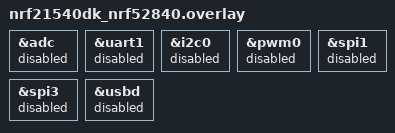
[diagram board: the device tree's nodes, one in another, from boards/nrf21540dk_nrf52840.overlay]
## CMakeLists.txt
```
#
# Copyright (c) 2021 Nordic Semiconductor ASA
#
# SPDX-License-Identifier: LicenseRef-Nordic-5-Clause
#

cmake_minimum_required(VERSION 3.20.0)

find_package(Zephyr HINTS $ENV{ZEPHYR_BASE})

project(matter-light-switch)

# Enable GNU STD support.
include(${ZEPHYR_CONNECTEDHOMEIP_MODULE_DIR}/config/nrfconnect/app/enable-gnu-std.cmake)

# NORDIC SDK APP START

# Include all source files that are located in the Matter common directory.
include(${ZEPHYR_NRF_MODULE_DIR}/samples/matter/common/cmake/source_common.cmake)

# Include Data Model utils
include(${ZEPHYR_NRF_MODULE_DIR}/samples/matter/common/cmake/data_model.cmake)

include(${ZEPHYR_NRF_MODULE_DIR}/samples/matter/common/cmake/zap_helpers.cmake)
ncs_get_zap_parent_dir(ZAP_PARENT_DIR)

target_include_directories(app PRIVATE
  src
  ${ZAP_PARENT_DIR}
)

target_compile_options(app PRIVATE -Wno-deprecated-declarations)

target_sources(app PRIVATE
  src/app_task.cpp
  src/main.cpp
  src/shell_commands.cpp
  ${ZEPHYR_NRF_MODULE_DIR}/samples/matter/common/src/binding/binding_handler.cpp
)

target_sources_ifdef(CONFIG_GENERIC_SWITCH app PRIVATE src/generic_switch.cpp)
target_sources_ifdef(CONFIG_LIGHT_SWITCH app PRIVATE src/light_switch.cpp)

ncs_configure_data_model()
# NORDIC SDK APP END
```

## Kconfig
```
#
# Copyright (c) 2022 Nordic Semiconductor
#
# SPDX-License-Identifier: LicenseRef-Nordic-5-Clause
#
mainmenu "Matter nRF Connect Light Switch Example Application"

config STATE_LEDS
	bool "Use LEDs to indicate the device state"
	default y
	help
	  Use LEDs to render the current state of the device such as the progress of commissioning of
	  the device into a network or the factory reset initiation. Note that setting this option to
	  'n' does not disable the LED indicating the state of the simulated bolt.

choice SWITCH_TYPE
	prompt "Matter Switch Type"
	default LIGHT_SWITCH
	help
	  Choose the type of switch to act as.

config LIGHT_SWITCH
	bool "Act as a Light Switch"
	help
	  Act as a Light Switch, which uses client application clusters (for example, Level Control) and bindings to send commands to the server clusters.

config GENERIC_SWITCH
	bool "Act as a Generic Switch"
	help
	  Act as a Generic Switch, which implements the Momentary Switch (`MS`) and Momentary Switch Release (`MSR`) features.

endchoice

# Sample configuration used for Thread networking
if OPENTHREAD

choice OPENTHREAD_NORDIC_LIBRARY_CONFIGURATION
	default OPENTHREAD_NORDIC_LIBRARY_MTD
endchoice

choice OPENTHREAD_DEVICE_TYPE
	default OPENTHREAD_MTD
endchoice

config CHIP_ENABLE_ICD_SUPPORT
	default y

# Reduce Thread TX output power to 0 dBm for SED device
config OPENTHREAD_DEFAULT_TX_POWER
	default 0

endif # OPENTHREAD

if BOARD_NRF7002DK_NRF5340_CPUAPP || SHIELD_NRF7002EB2

config CHIP_WIFI
	default y
	select DEPRECATED if SOC_SERIES_NRF53X

config NRF_WIFI_LOW_POWER
	default y

endif # BOARD_NRF7002DK_NRF5340_CPUAPP || SHIELD_NRF7002EB2

# Enable Read Client functionality for all build configurations.
config CHIP_ENABLE_READ_CLIENT
	default y

source "$(ZEPHYR_CONNECTEDHOMEIP_MODULE_DIR)/config/nrfconnect/chip-module/Kconfig.features"
source "$(ZEPHYR_CONNECTEDHOMEIP_MODULE_DIR)/config/nrfconnect/chip-module/Kconfig.defaults"
source "$(ZEPHYR_NRF_MODULE_DIR)/samples/matter/common/src/Kconfig"
source "Kconfig.zephyr"
```

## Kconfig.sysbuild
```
#
# Copyright (c) 2023 Nordic Semiconductor ASA
#
# SPDX-License-Identifier: LicenseRef-Nordic-5-Clause
#

config PARTITION_MANAGER
	default n if SOC_SERIES_NRF52X || SOC_NRF54L15 || SOC_NRF54LM20A

# This config has to be enabled manually for variants with shields, because sysbuild does not support it.
config WIFI_NRF70
	default y if BOARD_NRF7002DK

#### Radio core selection
config NRF_DEFAULT_IPC_RADIO
	default y

# Enable IEEE802.15.4 serialization to network core
# This config automatically pulls in the `overlay-802154.conf` in the ipc_radio image
config NETCORE_IPC_RADIO_IEEE802154
	default y if SOC_SERIES_NRF53X && !WIFI_NRF70

# Enable Bluetooth serialization to network core
# This config automatically pulls in the `overlay-bt_hci_ipc.conf` in the ipc_radio image
config NETCORE_IPC_RADIO_BT_HCI_IPC
	default y if SOC_SERIES_NRF53X

#### Bootloader
choice BOOTLOADER
	default BOOTLOADER_MCUBOOT if !BOARD_NRF21540DK
endchoice

if BOOTLOADER_MCUBOOT

#### DFU multi-image support
config DFU_MULTI_IMAGE_PACKAGE_BUILD
	default y

config DFU_MULTI_IMAGE_PACKAGE_APP
	default y

config PM_EXTERNAL_FLASH_MCUBOOT_SECONDARY
	default y

#### DFU network core configuration
if SOC_SERIES_NRF53X

choice MCUBOOT_MODE
	default MCUBOOT_MODE_OVERWRITE_ONLY
endchoice

choice BOOT_SIGNATURE_TYPE
	default BOOT_SIGNATURE_TYPE_RSA
endchoice

config SECURE_BOOT_NETCORE
	default y

config NETCORE_APP_UPDATE
	default y

config DFU_MULTI_IMAGE_PACKAGE_NET
	default y

endif # SOC_SERIES_NRF53X

if BOARD_NRF54L15DK || BOARD_NRF54LM20DK

# Disable checking the external drivers for nRF54L15 and nRF54LM20 DKs.
config PM_OVERRIDE_EXTERNAL_DRIVER_CHECK
	default y

endif # BOARD_NRF54L15DK || BOARD_NRF54LM20DK

endif # BOOTLOADER_MCUBOOT

# Store the Wi-Fi firmware patch on external flash by default for nRF5340 with nRF7002
if WIFI_NRF70 && SOC_NRF5340_CPUAPP

choice WIFI_PATCHES_EXT_FLASH_SUPPORT
	default WIFI_PATCHES_EXT_FLASH_STORE

endchoice

config DFU_MULTI_IMAGE_PACKAGE_WIFI_FW_PATCH
	default y

endif # WIFI_NRF70

#### Enable generating factory data
config MATTER_FACTORY_DATA_GENERATE
	default y if !BOARD_NRF21540DK

source "share/sysbuild/Kconfig"
```

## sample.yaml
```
sample:
  description: Matter Light Switch example
  name: Matter Light Switch
common:
  tags:
    - sysbuild
    - ci_samples_matter
tests:
  sample.matter.light_switch.debug:
    sysbuild: true
    build_only: true
    integration_platforms:
      - nrf52840dk/nrf52840
      - nrf5340dk/nrf5340/cpuapp
      - nrf7002dk/nrf5340/cpuapp
      - nrf54l15dk/nrf54l15/cpuapp
      - nrf54l15dk/nrf54l15/cpuapp/ns
      - nrf54lm20dk/nrf54lm20a/cpuapp
    platform_allow:
      - nrf52840dk/nrf52840
      - nrf5340dk/nrf5340/cpuapp
      - nrf7002dk/nrf5340/cpuapp
      - nrf54l15dk/nrf54l15/cpuapp
      - nrf54l15dk/nrf54l15/cpuapp/ns
      - nrf54lm20dk/nrf54lm20a/cpuapp
  sample.matter.light_switch.nrf7002eb2.debug:
    sysbuild: true
    build_only: true
    extra_args:
      - light_switch_SHIELD=nrf7002eb2
      - SB_CONFIG_WIFI_NRF70=y
    integration_platforms:
      - nrf54lm20dk/nrf54lm20a/cpuapp
    platform_allow:
      - nrf54lm20dk/nrf54lm20a/cpuapp
  sample.matter.light_switch.release:
    sysbuild: true
    build_only: true
    extra_args:
      - FILE_SUFFIX=release
      - SB_CONFIG_BOOTLOADER_MCUBOOT=y
      - SB_CONFIG_PARTITION_MANAGER=y
    integration_platforms:
      - nrf52840dk/nrf52840
      - nrf5340dk/nrf5340/cpuapp
      - nrf7002dk/nrf5340/cpuapp
      - nrf54l15dk/nrf54l15/cpuapp
      - nrf54lm20dk/nrf54lm20a/cpuapp
    platform_allow:
      - nrf52840dk/nrf52840
      - nrf5340dk/nrf5340/cpuapp
      - nrf7002dk/nrf5340/cpuapp
      - nrf54l15dk/nrf54l15/cpuapp
      - nrf54lm20dk/nrf54lm20a/cpuapp
  sample.matter.light_switch.nrf7002eb2.release:
    sysbuild: true
    build_only: true
    extra_args:
      - FILE_SUFFIX=release
      - SB_CONFIG_BOOTLOADER_MCUBOOT=y
      - SB_CONFIG_PARTITION_MANAGER=y
      - light_switch_SHIELD=nrf7002eb2
      - SB_CONFIG_WIFI_NRF70=y
    integration_platforms:
      - nrf54lm20dk/nrf54lm20a/cpuapp
    platform_allow:
      - nrf54lm20dk/nrf54lm20a/cpuapp
  sample.matter.light_switch.lit_icd:
    sysbuild: true
    build_only: true
    extra_args:
      - light_switch_SNIPPET=lit_icd
    integration_platforms:
      - nrf52840dk/nrf52840
      - nrf5340dk/nrf5340/cpuapp
      - nrf54l15dk/nrf54l15/cpuapp
    platform_allow:
      - nrf52840dk/nrf52840
      - nrf5340dk/nrf5340/cpuapp
      - nrf54l15dk/nrf54l15/cpuapp
  sample.matter.light_switch.low_power:
    sysbuild: true
    build_only: true
    extra_args:
      - FILE_SUFFIX=release
      - CONFIG_CHIP_ICD_SLOW_POLL_INTERVAL=7500
      - CONFIG_CHIP_ICD_ACTIVE_MODE_DURATION=800
      - CONFIG_CHIP_ICD_FAST_POLLING_INTERVAL=100
      - CONFIG_CHIP_ICD_ACTIVE_MODE_THRESHOLD=5000
      - CONFIG_OPENTHREAD_DEFAULT_TX_POWER=0
      - CONFIG_NCS_SAMPLE_MATTER_LEDS=n
      - CONFIG_NCS_SAMPLE_MATTER_WATCHDOG=n
      - CONFIG_CHIP_ENABLE_PAIRING_AUTOSTART=y
      - OVERLAY_CONFIG=overlay-generic_switch.conf
    integration_platforms:
      - nrf54lm20dk/nrf54lm20a/cpuapp
    platform_allow:
      - nrf54lm20dk/nrf54lm20a/cpuapp
  sample.matter.light_switch.low_power_dut:
    sysbuild: true
    build_only: true
    extra_args:
      - FILE_SUFFIX=release
      - CONFIG_CHIP_ICD_SLOW_POLL_INTERVAL=7500
      - CONFIG_CHIP_ICD_ACTIVE_MODE_DURATION=800
      - CONFIG_CHIP_ICD_FAST_POLLING_INTERVAL=100
      - CONFIG_CHIP_ICD_ACTIVE_MODE_THRESHOLD=5000
      - CONFIG_OPENTHREAD_DEFAULT_TX_POWER=5
      - CONFIG_NCS_SAMPLE_MATTER_LEDS=n
      - CONFIG_NCS_SAMPLE_MATTER_WATCHDOG=n
      - CONFIG_CHIP_ENABLE_PAIRING_AUTOSTART=y
      - OVERLAY_CONFIG=overlay-generic_switch.conf
    integration_platforms:
      - nrf54lm20dk/nrf54lm20a/cpuapp
    platform_allow:
      - nrf54lm20dk/nrf54lm20a/cpuapp
  sample.matter.light_switch.low_power_max:
    sysbuild: true
    build_only: true
    extra_args:
      - FILE_SUFFIX=release
      - CONFIG_CHIP_ICD_SLOW_POLL_INTERVAL=7500
      - CONFIG_CHIP_ICD_ACTIVE_MODE_DURATION=800
      - CONFIG_CHIP_ICD_FAST_POLLING_INTERVAL=100
      - CONFIG_CHIP_ICD_ACTIVE_MODE_THRESHOLD=5000
      - CONFIG_OPENTHREAD_DEFAULT_TX_POWER=8
      - CONFIG_NCS_SAMPLE_MATTER_LEDS=n
      - CONFIG_NCS_SAMPLE_MATTER_WATCHDOG=n
      - CONFIG_CHIP_ENABLE_PAIRING_AUTOSTART=y
      - OVERLAY_CONFIG=overlay-generic_switch.conf
    integration_platforms:
      - nrf54lm20dk/nrf54lm20a/cpuapp
    platform_allow:
      - nrf54lm20dk/nrf54lm20a/cpuapp
```

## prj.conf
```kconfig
#
# Copyright (c) 2021 Nordic Semiconductor ASA
#
# SPDX-License-Identifier: LicenseRef-Nordic-5-Clause
#

# Enable CHIP
CONFIG_CHIP=y
CONFIG_CHIP_PROJECT_CONFIG="src/chip_project_config.h"
CONFIG_CHIP_DEVICE_PRODUCT_NAME="Matter Light Switch"

# Configure ZAP file name
CONFIG_NCS_SAMPLE_MATTER_ZAP_FILE_PATH="${APPLICATION_CONFIG_DIR}/src/default_zap/light_switch.zap"

# 32772 == 0x8004 (example light-switch-app)
CONFIG_CHIP_DEVICE_PRODUCT_ID=32772
CONFIG_STD_CPP17=y

# Enable Matter pairing automatically on application start.
CONFIG_CHIP_ENABLE_PAIRING_AUTOSTART=y

# Enable Matter extended announcement and increase duration to 1 hour.
CONFIG_CHIP_BLE_EXT_ADVERTISING=y
CONFIG_CHIP_BLE_ADVERTISING_DURATION=60

# Add support for LEDs and buttons on Nordic development kits
CONFIG_DK_LIBRARY=y

# Bluetooth Low Energy configuration
CONFIG_BT_DEVICE_NAME="MatterSwitch"

# Suspend devices when the CPU goes into sleep
CONFIG_PM_DEVICE=y

# Other settings
CONFIG_THREAD_NAME=y
CONFIG_MPU_STACK_GUARD=y
CONFIG_RESET_ON_FATAL_ERROR=n
CONFIG_CHIP_LIB_SHELL=y
CONFIG_NCS_SAMPLE_MATTER_TEST_SHELL=y

# Reduce application size
CONFIG_USE_SEGGER_RTT=n

# Enable Factory Data feature
CONFIG_CHIP_FACTORY_DATA=y
CONFIG_CHIP_FACTORY_DATA_BUILD=y

# Enable LIT ICD configuration
CONFIG_CHIP_ICD_LIT_SUPPORT=y
CONFIG_CHIP_ICD_SIT_SLOW_POLL_LIMIT=5000
CONFIG_CHIP_ICD_REPORT_ON_ACTIVE_MODE=y
```

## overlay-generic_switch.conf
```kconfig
#
# Copyright (c) 2026 Nordic Semiconductor ASA
#
# SPDX-License-Identifier: LicenseRef-Nordic-5-Clause
#

CONFIG_GENERIC_SWITCH=y
CONFIG_NCS_SAMPLE_MATTER_ZAP_FILE_PATH="${APPLICATION_CONFIG_DIR}/src/generic_switch_zap/generic_switch.zap"
```

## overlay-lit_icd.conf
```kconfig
#
# Copyright (c) 2026 Nordic Semiconductor ASA
#
# SPDX-License-Identifier: LicenseRef-Nordic-5-Clause
#
```

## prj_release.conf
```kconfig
#
# Copyright (c) 2021 Nordic Semiconductor ASA
#
# SPDX-License-Identifier: LicenseRef-Nordic-5-Clause
#

# Enable CHIP
CONFIG_CHIP=y
CONFIG_CHIP_PROJECT_CONFIG="src/chip_project_config.h"
CONFIG_CHIP_DEVICE_PRODUCT_NAME="Matter Light Switch"

# Configure ZAP file name
CONFIG_NCS_SAMPLE_MATTER_ZAP_FILE_PATH="${APPLICATION_CONFIG_DIR}/src/default_zap/light_switch.zap"

# 32772 == 0x8004 (example light-switch-app)
CONFIG_CHIP_DEVICE_PRODUCT_ID=32772
CONFIG_STD_CPP17=y

# Enable Matter pairing automatically on application start.
CONFIG_CHIP_ENABLE_PAIRING_AUTOSTART=y

# Enable Matter extended announcement and increase duration to 1 hour.
CONFIG_CHIP_BLE_EXT_ADVERTISING=y
CONFIG_CHIP_BLE_ADVERTISING_DURATION=60

# Add support for LEDs and buttons on Nordic development kits
CONFIG_DK_LIBRARY=y

# Try to disable unused RAM blocks to reduce power consumption
CONFIG_RAM_POWER_DOWN_LIBRARY=y

# Bluetooth Low Energy configuration
CONFIG_BT_DEVICE_NAME="MatterSwitch"

# Suspend devices when the CPU goes into sleep
CONFIG_PM_DEVICE=y

# Enable system reset on fatal error
CONFIG_RESET_ON_FATAL_ERROR=y

# Disable all debug features
CONFIG_USE_SEGGER_RTT=n
CONFIG_SHELL=n
CONFIG_OPENTHREAD_SHELL=n
CONFIG_CONSOLE=n
CONFIG_UART_CONSOLE=n
CONFIG_SERIAL=n
CONFIG_LOG=n
CONFIG_LOG_MODE_MINIMAL=n
CONFIG_ASSERT_VERBOSE=n
CONFIG_ASSERT_NO_FILE_INFO=y
CONFIG_PRINTK=n
CONFIG_PRINTK_SYNC=n
CONFIG_THREAD_NAME=n
CONFIG_BOOT_BANNER=n

# Enable Factory Data feature
CONFIG_CHIP_FACTORY_DATA=y
CONFIG_CHIP_FACTORY_DATA_BUILD=y

# Enable Watchdog
CONFIG_NCS_SAMPLE_MATTER_WATCHDOG=y

# Enable LTO to decrease the flash usage.
CONFIG_LTO=y
CONFIG_ISR_TABLES_LOCAL_DECLARATION=y

# Enable LIT ICD configuration
CONFIG_CHIP_ICD_LIT_SUPPORT=y
CONFIG_CHIP_ICD_SIT_SLOW_POLL_LIMIT=5000
CONFIG_CHIP_ICD_REPORT_ON_ACTIVE_MODE=y
```

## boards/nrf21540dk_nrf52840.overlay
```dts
/* Copyright (c) 2021 Nordic Semiconductor ASA
 *
 * SPDX-License-Identifier: LicenseRef-Nordic-5-Clause
 */

#include <samples/matter/nrf52840_partitions.dtsi>

/* Disable unused peripherals to reduce power consumption */
&adc {
	status = "disabled";
};

&uart1 {
	status = "disabled";
};

&i2c0 {
	status = "disabled";
};

&pwm0 {
	status = "disabled";
};

&spi1 {
	status = "disabled";
};

&spi3 {
	status = "disabled";
};

&usbd {
	status = "disabled";
};
```

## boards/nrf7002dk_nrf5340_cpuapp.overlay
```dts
/*
 * Copyright (c) 2021 Nordic Semiconductor ASA
 *
 * SPDX-License-Identifier: LicenseRef-Nordic-5-Clause
 */

#include <samples/matter/nrf7002_partitions.dtsi>
#include <zephyr/dt-bindings/ipc_service/static_vrings.h>

/ {
	aliases {
		watchdog0 = &wdt0;
	};
};

/* Set IPC thread priority to the highest value to not collide with other threads. */
&ipc0 {
	zephyr,priority = <0 PRIO_COOP>;
};
```

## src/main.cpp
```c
/*
 * Copyright (c) 2022 Nordic Semiconductor ASA
 *
 * SPDX-License-Identifier: LicenseRef-Nordic-5-Clause
 */

#include "app_task.h"

#include <cstdlib>
#include <logging/log.h>

LOG_MODULE_REGISTER(app);

int main()
{
	return GetAppTask().StartApp() == CHIP_NO_ERROR ? EXIT_SUCCESS : EXIT_FAILURE;
}
```

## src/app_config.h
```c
/*
 * Copyright (c) 2022 Nordic Semiconductor ASA
 *
 * SPDX-License-Identifier: LicenseRef-Nordic-5-Clause
 */

#pragma once

// ---- Lighting Example App Config ----

#define FUNCTION_BUTTON DK_BTN1
#define FUNCTION_BUTTON_MASK DK_BTN1_MSK
#define SWITCH_BUTTON DK_BTN2
#define SWITCH_BUTTON_MASK DK_BTN2_MSK
#define BLE_ADVERTISEMENT_START_BUTTON DK_BTN4
#define BLE_ADVERTISEMENT_START_BUTTON_MASK DK_BTN4_MSK

#define SYSTEM_STATE_LED DK_LED1
#define DFU_BLE_LED DK_LED2
#define IDENTIFY_LED DK_LED3
```

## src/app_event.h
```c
/*
 * Copyright (c) 2021 Nordic Semiconductor ASA
 *
 * SPDX-License-Identifier: LicenseRef-Nordic-5-Clause
 */

#pragma once

#include <inet/IPAddress.h>

#include <cstdint>

#include "led_widget.h"

struct AppEvent;
typedef void (*EventHandler)(AppEvent *);

struct AppEvent {
	constexpr static uint8_t kButtonPushEvent = 1;
	constexpr static uint8_t kButtonReleaseEvent = 0;

	enum AppEventTypes : uint8_t {
		kEventType_StartBLEAdvertising,
		kEventType_Button,
		kEventType_Timer,
		kEventType_UpdateLedState,
		kEventType_IdentifyStart,
		kEventType_IdentifyStop,
#ifdef CONFIG_MCUMGR_SMP_BT
		kEventType_StartSMPAdvertising,
#endif
	};

	uint8_t Type;

	union {
		struct {
			uint8_t PinNo;
			uint8_t Action;
		} ButtonEvent;
		struct {
			uint8_t TimerType;
			void *Context;
		} TimerEvent;
		struct {
			LEDWidget *LedWidget;
		} UpdateLedStateEvent;
	};

	EventHandler Handler;
};
```

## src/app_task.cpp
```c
/*
 * Copyright (c) 2022 Nordic Semiconductor ASA
 *
 * SPDX-License-Identifier: LicenseRef-Nordic-5-Clause
 */

#include "app_task.h"

#if defined(CONFIG_LIGHT_SWITCH)
#include "light_switch.h"
#elif defined(CONFIG_GENERIC_SWITCH)
#include "generic_switch.h"
#endif

#include "app/matter_init.h"
#include "app/task_executor.h"
#include "board/board.h"
#include "clusters/identify.h"

#include <setup_payload/OnboardingCodesUtil.h>

#include <zephyr/logging/log.h>

LOG_MODULE_DECLARE(app, CONFIG_CHIP_APP_LOG_LEVEL);

using namespace ::chip;
using namespace ::chip::app;
using namespace ::chip::DeviceLayer;

namespace
{
constexpr uint32_t kDimmerTriggeredTimeout = 500;
constexpr uint32_t kDimmerInterval = 300;
constexpr EndpointId kLightSwitchEndpointId = 1;
constexpr EndpointId kLightEndpointId = 1;

k_timer sDimmerPressKeyTimer;
k_timer sDimmerTimer;

Nrf::Matter::IdentifyCluster sIdentifyCluster(kLightEndpointId);

bool sWasDimmerTriggered = false;

#define APPLICATION_BUTTON_MASK DK_BTN2_MSK

#ifdef CONFIG_CHIP_ICD_UAT_SUPPORT
#define UAT_BUTTON_MASK DK_BTN3_MSK
#endif

#if defined(CONFIG_LIGHT_SWITCH)
	LightSwitch sSwitchInstance(kLightSwitchEndpointId);
#elif defined(CONFIG_GENERIC_SWITCH)
	GenericSwitch sSwitchInstance(kLightSwitchEndpointId);
#endif
} /* namespace */

void AppTask::DimmerTriggerEventHandler()
{
	if (!sWasDimmerTriggered) {
		sSwitchInstance.InitiateActionSwitch(LightSwitch::Action::Toggle);
	}

	Instance().CancelTimer(Timer::Dimmer);
	Instance().CancelTimer(Timer::DimmerTrigger);
	sWasDimmerTriggered = false;
}

void AppTask::TimerEventHandler(const Timer &timerType)
{
	switch (timerType) {
	case Timer::DimmerTrigger:
		LOG_INF("Dimming started...");
		sWasDimmerTriggered = true;
		sSwitchInstance.InitiateActionSwitch(LightSwitch::Action::On);
		Instance().StartTimer(Timer::Dimmer, kDimmerInterval);
		Instance().CancelTimer(Timer::DimmerTrigger);
		break;
	case Timer::Dimmer:
		sSwitchInstance.DimmerChangeBrightness();
		break;
	default:
		break;
	}
}

void AppTask::ButtonEventHandler(Nrf::ButtonState state, Nrf::ButtonMask hasChanged)
{
	if ((APPLICATION_BUTTON_MASK & state & hasChanged)) {
		LOG_INF("Button has been pressed, keep in this state for at least 500 ms to change light sensitivity of bound lighting devices.");
		Instance().StartTimer(Timer::DimmerTrigger, kDimmerTriggeredTimeout);
	} else if ((APPLICATION_BUTTON_MASK & hasChanged)) {
		Nrf::PostTask([] { DimmerTriggerEventHandler(); });
#ifdef CONFIG_CHIP_ICD_UAT_SUPPORT
	} else if ((UAT_BUTTON_MASK & state & hasChanged)) {
		LOG_INF("ICD UserActiveMode has been triggered.");
		Server::GetInstance().GetICDManager().OnNetworkActivity();
#endif
	}
}

void AppTask::StartTimer(Timer timer, uint32_t timeoutMs)
{
	switch (timer) {
	case Timer::DimmerTrigger:
		k_timer_start(&sDimmerPressKeyTimer, K_MSEC(timeoutMs), K_NO_WAIT);
		break;
	case Timer::Dimmer:
		k_timer_start(&sDimmerTimer, K_MSEC(timeoutMs), K_MSEC(timeoutMs));
		break;
	default:
		break;
	}
}

void AppTask::CancelTimer(Timer timer)
{
	switch (timer) {
	case Timer::DimmerTrigger:
		k_timer_stop(&sDimmerPressKeyTimer);
		break;
	case Timer::Dimmer:
		k_timer_stop(&sDimmerTimer);
		break;
	default:
		break;
	}
}

void AppTask::UserTimerTimeoutCallback(k_timer *timer)
{
	if (!timer) {
		return;
	}
	Timer timerType;

	if (timer == &sDimmerPressKeyTimer) {
		timerType = Timer::DimmerTrigger;
	} else if (timer == &sDimmerTimer) {
		timerType = Timer::Dimmer;
	} else {
		return;
	}

	Nrf::PostTask([timerType]() { TimerEventHandler(timerType); });
}

CHIP_ERROR AppTask::Init()
{
	/* Initialize Matter stack */
	ReturnErrorOnFailure(Nrf::Matter::PrepareServer(Nrf::Matter::InitData{ .mPostServerInitClbk = [] {
		sSwitchInstance.Init();
		return CHIP_NO_ERROR;
	} }));

	/* Initialize application timers */
	k_timer_init(&sDimmerPressKeyTimer, AppTask::UserTimerTimeoutCallback, nullptr);
	k_timer_init(&sDimmerTimer, AppTask::UserTimerTimeoutCallback, nullptr);

	if (!Nrf::GetBoard().Init(ButtonEventHandler)) {
		LOG_ERR("User interface initialization failed.");
		return CHIP_ERROR_INCORRECT_STATE;
	}

	/* Register Matter event handler that controls the connectivity status LED based on the captured Matter network
	 * state. */
	ReturnErrorOnFailure(Nrf::Matter::RegisterEventHandler(Nrf::Board::DefaultMatterEventHandler, 0));

	ReturnErrorOnFailure(sIdentifyCluster.Init());

	return Nrf::Matter::StartServer();
}

CHIP_ERROR AppTask::StartApp()
{
	ReturnErrorOnFailure(Init());

	while (true) {
		Nrf::DispatchNextTask();
	}

	return CHIP_NO_ERROR;
}
```

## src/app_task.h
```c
/*
 * Copyright (c) 2022 Nordic Semiconductor ASA
 *
 * SPDX-License-Identifier: LicenseRef-Nordic-5-Clause
 */

#pragma once

#include "app_event.h"
#include "led_widget.h"

#include <core/CHIPError.h>
#include <platform/CHIPDeviceLayer.h>

#ifdef CONFIG_MCUMGR_SMP_BT
#include "DFUOverSMP.h"
#endif

#include <cstdint>

struct k_timer;
struct Identify;

class AppTask {
public:
	CHIP_ERROR StartApp();
	void PostEvent(AppEvent *);
	void UpdateClusterState();
	static void IdentifyStartHandler(Identify *);
	static void IdentifyStopHandler(Identify *);

private:
	enum class Timer : uint8_t { Function, DimmerTrigger, Dimmer };
	enum class TimerFunction : uint8_t { NoneSelected = 0, SoftwareUpdate, FactoryReset };
	TimerFunction mFunction = TimerFunction::NoneSelected;

	enum class Button : uint8_t {
		Function,
		Dimmer,
	};

	friend AppTask &GetAppTask();
	static AppTask sAppTask;

	CHIP_ERROR Init();

	void DispatchEvent(AppEvent *);
	void InitOTARequestor();

	static void ButtonPushHandler(AppEvent *);
	static void ButtonReleaseHandler(AppEvent *);
	static void TimerEventHandler(AppEvent *);
	static void StartBLEAdvertisingHandler(AppEvent *);
	static void UpdateLedStateEventHandler(AppEvent *);

	static void ChipEventHandler(const chip::DeviceLayer::ChipDeviceEvent *, intptr_t);
	static void UpdateStatusLED();
	static void ButtonEventHandler(uint32_t, uint32_t);
	static void LEDStateUpdateHandler(LEDWidget &);

	static void StartTimer(Timer, uint32_t);
	static void CancelTimer(Timer);
	static void TimerEventHandler(k_timer *);

#ifdef CONFIG_MCUMGR_SMP_BT
	static void RequestSMPAdvertisingStart(void);
#endif
};

inline AppTask &GetAppTask()
{
	return AppTask::sAppTask;
}
```

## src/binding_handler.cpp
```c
/*
 * Copyright (c) 2022 Nordic Semiconductor ASA
 *
 * SPDX-License-Identifier: LicenseRef-Nordic-5-Clause
 */

#include "binding_handler.h"
#ifdef CONFIG_CHIP_LIB_SHELL
#include "shell_commands.h"
#endif

#include <app/clusters/bindings/bindings.h>
#include <zephyr/logging/log.h>

LOG_MODULE_DECLARE(app, CONFIG_MATTER_LOG_LEVEL);

using namespace chip;
using namespace chip::app;

void BindingHandler::Init()
{
#ifdef CONFIG_CHIP_LIB_SHELL
	SwitchCommands::RegisterSwitchCommands();
#endif
	DeviceLayer::PlatformMgr().ScheduleWork(InitInternal);
}

void BindingHandler::OnInvokeCommandFailure(BindingData &aBindingData, CHIP_ERROR aError)
{
	CHIP_ERROR error;

	if (aError == CHIP_ERROR_TIMEOUT && !BindingHandler::GetInstance().mCaseSessionRecovered) {
		LOG_INF("Response timeout for invoked command, trying to recover CASE session.");

		/* Set flag to not try recover session multiple times. */
		BindingHandler::GetInstance().mCaseSessionRecovered = true;

		/* Allocate new object to make sure its life time will be appropriate. */
		BindingHandler::BindingData *data = Platform::New<BindingHandler::BindingData>();
		*data = aBindingData;

		/* Establish new CASE session and retrasmit command that was not applied. */
		error = BindingManager::GetInstance().NotifyBoundClusterChanged(
			aBindingData.EndpointId, aBindingData.ClusterId, static_cast<void *>(data));

		if (CHIP_NO_ERROR != error) {
			LOG_ERR("NotifyBoundClusterChanged failed due to: %" CHIP_ERROR_FORMAT, error.Format());
			return;
		}
	} else {
		LOG_ERR("Binding command was not applied! Reason: %" CHIP_ERROR_FORMAT, aError.Format());
	}
}

void BindingHandler::OnOffProcessCommand(CommandId aCommandId, const EmberBindingTableEntry &aBinding,
					 OperationalDeviceProxy *aDevice, void *aContext)
{
	CHIP_ERROR ret = CHIP_NO_ERROR;
	BindingData *data = reinterpret_cast<BindingData *>(aContext);

	auto onSuccess = [](const ConcreteCommandPath &commandPath, const StatusIB &status, const auto &dataResponse) {
		LOG_DBG("Binding command applied successfully!");

		/* If session was recovered and communication works, reset flag to the initial state. */
		if (BindingHandler::GetInstance().mCaseSessionRecovered)
			BindingHandler::GetInstance().mCaseSessionRecovered = false;
	};

	auto onFailure = [dataRef = *data](CHIP_ERROR aError) mutable {
		BindingHandler::OnInvokeCommandFailure(dataRef, aError);
	};

	if (aDevice) {
		/* We are validating connection is ready once here instead of multiple times in each case statement
		 * below. */
		VerifyOrDie(aDevice->ConnectionReady());
	}

	switch (aCommandId) {
	case Clusters::OnOff::Commands::Toggle::Id:
		Clusters::OnOff::Commands::Toggle::Type toggleCommand;
		if (aDevice) {
			ret = Controller::InvokeCommandRequest(aDevice->GetExchangeManager(),
							       aDevice->GetSecureSession().Value(), aBinding.remote,
							       toggleCommand, onSuccess, onFailure);
		} else {
			Messaging::ExchangeManager &exchangeMgr = Server::GetInstance().GetExchangeManager();
			ret = Controller::InvokeGroupCommandRequest(&exchangeMgr, aBinding.fabricIndex,
								    aBinding.groupId, toggleCommand);
		}
		break;

	case Clusters::OnOff::Commands::On::Id:
		Clusters::OnOff::Commands::On::Type onCommand;
		if (aDevice) {
			ret = Controller::InvokeCommandRequest(aDevice->GetExchangeManager(),
							       aDevice->GetSecureSession().Value(), aBinding.remote,
							       onCommand, onSuccess, onFailure);
		} else {
			Messaging::ExchangeManager &exchangeMgr = Server::GetInstance().GetExchangeManager();
			ret = Controller::InvokeGroupCommandRequest(&exchangeMgr, aBinding.fabricIndex,
								    aBinding.groupId, onCommand);
		}
		break;

	case Clusters::OnOff::Commands::Off::Id:
		Clusters::OnOff::Commands::Off::Type offCommand;
		if (aDevice) {
			ret = Controller::InvokeCommandRequest(aDevice->GetExchangeManager(),
							       aDevice->GetSecureSession().Value(), aBinding.remote,
							       offCommand, onSuccess, onFailure);
		} else {
			Messaging::ExchangeManager &exchangeMgr = Server::GetInstance().GetExchangeManager();
			ret = Controller::InvokeGroupCommandRequest(&exchangeMgr, aBinding.fabricIndex,
								    aBinding.groupId, offCommand);
		}
		break;
	default:
		LOG_DBG("Invalid binding command data - commandId is not supported");
		break;
	}
	if (CHIP_NO_ERROR != ret) {
		LOG_ERR("Invoke OnOff Command Request ERROR: %s", ErrorStr(ret));
	}
}

void BindingHandler::LevelControlProcessCommand(CommandId aCommandId, const EmberBindingTableEntry &aBinding,
						OperationalDeviceProxy *aDevice, void *aContext)
{
	BindingData *data = reinterpret_cast<BindingData *>(aContext);

	auto onSuccess = [](const ConcreteCommandPath &commandPath, const StatusIB &status, const auto &dataResponse) {
		LOG_DBG("Binding command applied successfully!");

		/* If session was recovered and communication works, reset flag to the initial state. */
		if (BindingHandler::GetInstance().mCaseSessionRecovered)
			BindingHandler::GetInstance().mCaseSessionRecovered = false;
	};

	auto onFailure = [dataRef = *data](CHIP_ERROR aError) mutable {
		BindingHandler::OnInvokeCommandFailure(dataRef, aError);
	};

	CHIP_ERROR ret = CHIP_NO_ERROR;

	if (aDevice) {
		/* We are validating connection is ready once here instead of multiple times in each case statement
		 * below. */
		VerifyOrDie(aDevice->ConnectionReady());
	}

	switch (aCommandId) {
	case Clusters::LevelControl::Commands::MoveToLevel::Id: {
		Clusters::LevelControl::Commands::MoveToLevel::Type moveToLevelCommand;
		moveToLevelCommand.level = data->Value;
		if (aDevice) {
			ret = Controller::InvokeCommandRequest(aDevice->GetExchangeManager(),
							       aDevice->GetSecureSession().Value(), aBinding.remote,
							       moveToLevelCommand, onSuccess, onFailure);
		} else {
			Messaging::ExchangeManager &exchangeMgr = Server::GetInstance().GetExchangeManager();
			ret = Controller::InvokeGroupCommandRequest(&exchangeMgr, aBinding.fabricIndex,
								    aBinding.groupId, moveToLevelCommand);
		}
	} break;
	default:
		LOG_DBG("Invalid binding command data - commandId is not supported");
		break;
	}
	if (CHIP_NO_ERROR != ret) {
		LOG_ERR("Invoke Group Command Request ERROR: %s", ErrorStr(ret));
	}
}

void BindingHandler::LightSwitchChangedHandler(const EmberBindingTableEntry &binding,
					       OperationalDeviceProxy *deviceProxy, void *context)
{
	VerifyOrReturn(context != nullptr, LOG_ERR("Invalid context for Light switch handler"););
	BindingData *data = static_cast<BindingData *>(context);

	if (binding.type == EMBER_MULTICAST_BINDING && data->IsGroup) {
		switch (data->ClusterId) {
		case Clusters::OnOff::Id:
			OnOffProcessCommand(data->CommandId, binding, nullptr, context);
			break;
		case Clusters::LevelControl::Id:
			LevelControlProcessCommand(data->CommandId, binding, nullptr, context);
			break;
		default:
			ChipLogError(NotSpecified, "Invalid binding group command data");
			break;
		}
	} else if (binding.type == EMBER_UNICAST_BINDING && !data->IsGroup) {
		switch (data->ClusterId) {
		case Clusters::OnOff::Id:
			OnOffProcessCommand(data->CommandId, binding, deviceProxy, context);
			break;
		case Clusters::LevelControl::Id:
			LevelControlProcessCommand(data->CommandId, binding, deviceProxy, context);
			break;
		default:
			ChipLogError(NotSpecified, "Invalid binding unicast command data");
			break;
		}
	}
}

void BindingHandler::LightSwitchContextReleaseHandler(void *context)
{
	VerifyOrReturn(context != nullptr, LOG_ERR("Invalid context for Light switch context release handler"););

	Platform::Delete(static_cast<BindingData *>(context));
}

void BindingHandler::InitInternal(intptr_t aArg)
{
	LOG_INF("Initialize binding Handler");
	auto &server = Server::GetInstance();
	if (CHIP_NO_ERROR !=
	    BindingManager::GetInstance().Init(
		    { &server.GetFabricTable(), server.GetCASESessionManager(), &server.GetPersistentStorage() })) {
		LOG_ERR("BindingHandler::InitInternal failed");
	}

	BindingManager::GetInstance().RegisterBoundDeviceChangedHandler(LightSwitchChangedHandler);
	BindingManager::GetInstance().RegisterBoundDeviceContextReleaseHandler(LightSwitchContextReleaseHandler);
	BindingHandler::GetInstance().PrintBindingTable();
}

bool BindingHandler::IsGroupBound()
{
	BindingTable &bindingTable = BindingTable::GetInstance();

	for (auto &entry : bindingTable) {
		if (EMBER_MULTICAST_BINDING == entry.type) {
			return true;
		}
	}
	return false;
}

void BindingHandler::PrintBindingTable()
{
	BindingTable &bindingTable = BindingTable::GetInstance();

	LOG_INF("Binding Table size: [%d]:", bindingTable.Size());
	uint8_t i = 0;
	for (auto &entry : bindingTable) {
		switch (entry.type) {
		case EMBER_UNICAST_BINDING:
			LOG_INF("[%d] UNICAST:", i++);
			LOG_INF("\t\t+ Fabric: %d\n \
            \t+ LocalEndpoint %d \n \
            \t+ ClusterId %d \n \
            \t+ RemoteEndpointId %d \n \
            \t+ NodeId %d",
				(int)entry.fabricIndex, (int)entry.local, (int)entry.clusterId.Value(),
				(int)entry.remote, (int)entry.nodeId);
			break;
		case EMBER_MULTICAST_BINDING:
			LOG_INF("[%d] GROUP:", i++);
			LOG_INF("\t\t+ Fabric: %d\n \
            \t+ LocalEndpoint %d \n \
            \t+ RemoteEndpointId %d \n \
            \t+ GroupId %d",
				(int)entry.fabricIndex, (int)entry.local, (int)entry.remote, (int)entry.groupId);
			break;
		case EMBER_UNUSED_BINDING:
			LOG_INF("[%d] UNUSED", i++);
			break;
		case EMBER_MANY_TO_ONE_BINDING:
			LOG_INF("[%d] MANY TO ONE", i++);
			break;
		default:
			break;
		}
	}
}

void BindingHandler::SwitchWorkerHandler(intptr_t aContext)
{
	VerifyOrReturn(aContext != 0, LOG_ERR("Invalid Swich data"));

	BindingData *data = reinterpret_cast<BindingData *>(aContext);
	LOG_INF("Notify Bounded Cluster | endpoint: %d cluster: %d", data->EndpointId, data->ClusterId);
	BindingManager::GetInstance().NotifyBoundClusterChanged(data->EndpointId, data->ClusterId,
								static_cast<void *>(data));
}

void BindingHandler::BindingWorkerFunction(intptr_t context)
{
    VerifyOrReturn(context != 0, ChipLogError(NotSpecified, "Invalid new binding data"));

	LOG_INF("Adding a new binding entry...");

    EmberBindingTableEntry * entry = reinterpret_cast<EmberBindingTableEntry *>(context);
    AddBindingEntry(*entry);

    Platform::Delete(entry);
}

void BindingHandler::LookForDevices(intptr_t aContext)
{
	LOG_INF("Looking for Controllable devices...");
}
```

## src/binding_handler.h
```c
/*
 * Copyright (c) 2022 Nordic Semiconductor ASA
 *
 * SPDX-License-Identifier: LicenseRef-Nordic-5-Clause
 */
#pragma once

#include <app-common/zap-generated/ids/Clusters.h>
#include <app-common/zap-generated/ids/Commands.h>
#include <app/CommandSender.h>
#include <app/clusters/bindings/BindingManager.h>
#include <controller/InvokeInteraction.h>
#include <platform/CHIPDeviceLayer.h>
#include <lib/core/NodeId.h>

class BindingHandler {
public:
	struct BindingData {
		chip::EndpointId EndpointId;
		chip::CommandId CommandId;
		chip::ClusterId ClusterId;
		uint8_t Value;
		bool IsGroup{ false };
	};

	void Init();
	void PrintBindingTable();
	bool IsGroupBound();

	static void SwitchWorkerHandler(intptr_t);
	static void BindingWorkerFunction(intptr_t);
	static void LookForDevices(intptr_t aContext);
	static void OnInvokeCommandFailure(BindingData &aBindingData, CHIP_ERROR aError);

	static BindingHandler &GetInstance()
	{
		static BindingHandler sBindingHandler;
		return sBindingHandler;
	}

private:
	static void OnOffProcessCommand(chip::CommandId, const EmberBindingTableEntry &, chip::OperationalDeviceProxy *,
					void *);
	static void LevelControlProcessCommand(chip::CommandId, const EmberBindingTableEntry &,
					       chip::OperationalDeviceProxy *, void *);
	static void LightSwitchChangedHandler(const EmberBindingTableEntry &, chip::OperationalDeviceProxy *, void *);
	static void LightSwitchContextReleaseHandler(void *context);
	static void InitInternal(intptr_t);

	bool mCaseSessionRecovered = false;
};
```

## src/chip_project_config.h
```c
/*
 * Copyright (c) 2022 Nordic Semiconductor ASA
 *
 * SPDX-License-Identifier: LicenseRef-Nordic-5-Clause
 */

#pragma once

#define CHIP_CONFIG_CONTROLLER_MAX_ACTIVE_DEVICES 2
/* Use a default pairing code if one hasn't been provisioned in flash. */
#define CHIP_DEVICE_CONFIG_USE_TEST_SETUP_PIN_CODE 20202021
#define CHIP_DEVICE_CONFIG_USE_TEST_SETUP_DISCRIMINATOR 0xF00

/* When WiFi low power mode is enabled, 
 * increase MRP local active retry interval to work with 
 * 3 DTIMs and the Beacon interval equal to 102.4 ms.
*/
#ifdef CONFIG_NRF_WIFI_LOW_POWER
    #define CHIP_CONFIG_ALLOW_RUNTIME_MRP_OVERRIDE 1
#endif
```

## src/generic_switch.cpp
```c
/*
 * Copyright (c) 2026 Nordic Semiconductor ASA
 *
 * SPDX-License-Identifier: LicenseRef-Nordic-5-Clause
 */

#include "generic_switch.h"

#include <app-common/zap-generated/attributes/Accessors.h>
#include <app-common/zap-generated/cluster-objects.h>
#include <app/clusters/switch-server/switch-server.h>
#include <app/server/Server.h>
#include <platform/CHIPDeviceLayer.h>

#include <zephyr/logging/log.h>

#ifdef CONFIG_CHIP_LIB_SHELL
#include "shell_commands.h"
#endif

using namespace chip;
using namespace chip::app;
using namespace chip::app::Clusters;
using namespace chip::DeviceLayer;

LOG_MODULE_DECLARE(app, CONFIG_CHIP_APP_LOG_LEVEL);

void GenericSwitch::Init()
{
#ifdef CONFIG_CHIP_LIB_SHELL
	SwitchCommands::RegisterSwitchCommands();
#endif
}

void GenericSwitch::InitiateActionSwitch(Action action)
{
	switch (action) {
	case Action::Toggle:
		// Simulate a complete short press/release cycle for toggle
		InitialPressHandler();
		ShortReleaseHandler();
		break;
	default:
		break;
	}
}

void GenericSwitch::DimmerChangeBrightness()
{
	// Use long press handler for brightness changes
	// Each call represents a brightness step during dimming
	LongPressHandler();
}

void GenericSwitch::InitialPressHandler()
{
	// Press moves Position from 0 (idle) to 1 (press)
	uint8_t newPosition = 1;

	LOG_DBG("GenericSwitchInitialPress new position %d", newPosition);
	SystemLayer().ScheduleLambda([newPosition, this] {
		Clusters::Switch::Attributes::CurrentPosition::Set(this->mSwitchEndpoint, newPosition);
		// InitialPress event takes newPosition as event data
		SwitchServer::Instance().OnInitialPress(this->mSwitchEndpoint, newPosition);
	});
}

void GenericSwitch::ShortReleaseHandler()
{
	// Release moves Position from 1 (press) to 0 (idle)
	uint8_t previousPosition = 1;
	uint8_t newPosition = 0;

	LOG_DBG("GenericSwitchShortRelease new position %d", newPosition);
	SystemLayer().ScheduleLambda([newPosition, previousPosition, this] {
		Clusters::Switch::Attributes::CurrentPosition::Set(this->mSwitchEndpoint, newPosition);
		// Short Release event takes newPosition as event data
		SwitchServer::Instance().OnShortRelease(this->mSwitchEndpoint, previousPosition);
	});
}

void GenericSwitch::LongReleaseHandler()
{
	// Long release moves Position from 1 (press) to 0 (idle)
	uint8_t previousPosition = 1;
	uint8_t newPosition = 0;

	LOG_DBG("GenericSwitchLongRelease new position %d", newPosition);
	SystemLayer().ScheduleLambda([newPosition, previousPosition, this] {
		Clusters::Switch::Attributes::CurrentPosition::Set(this->mSwitchEndpoint, newPosition);
		// Long Release event takes newPosition as event data
		SwitchServer::Instance().OnLongRelease(this->mSwitchEndpoint, previousPosition);
	});
}

void GenericSwitch::LongPressHandler()
{
	// Long press moves Position from 0 (idle) to 1 (press)
	uint8_t newPosition = 1;

	LOG_DBG("GenericSwitchLongPress new position %d", newPosition);
	SystemLayer().ScheduleLambda([newPosition, this] {
		// LongPress event takes newPosition as event data
		SwitchServer::Instance().OnLongPress(this->mSwitchEndpoint, newPosition);
	});
}
```

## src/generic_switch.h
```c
/*
 * Copyright (c) 2026 Nordic Semiconductor ASA
 *
 * SPDX-License-Identifier: LicenseRef-Nordic-5-Clause
 */

#pragma once

#include "light_switch.h"


/** @class GenericSwitch
 *  @brief Class for controlling a CHIP generic switch over a Thread network
 *
 *  Features:
 *  - implementing the Momentary Switch (`MS`) and Momentary Switch Release (`MSR`) features.
 */
class GenericSwitch : public Switch {

public:
    void Init() override;
    void InitiateActionSwitch(Action action) override;
    void DimmerChangeBrightness() override;

    GenericSwitch(chip::EndpointId switchEndpoint) : Switch(switchEndpoint) {}

private:

    void InitialPressHandler();
    void ShortReleaseHandler();
    void LongReleaseHandler();
    void LongPressHandler();
};
```

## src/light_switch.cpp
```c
/*
 * Copyright (c) 2022 Nordic Semiconductor ASA
 *
 * SPDX-License-Identifier: LicenseRef-Nordic-5-Clause
 */

#include "light_switch.h"
#include "binding/binding_handler.h"

#ifdef CONFIG_CHIP_LIB_SHELL
#include "shell_commands.h"
#endif

#include <app/clusters/bindings/binding-table.h>
#include <app/server/Server.h>
#include <controller/InvokeInteraction.h>
#include <platform/CHIPDeviceLayer.h>
#include <zephyr/logging/log.h>

using namespace chip;
using namespace chip::app;
using namespace chip::app::Clusters;

LOG_MODULE_DECLARE(app, CONFIG_CHIP_APP_LOG_LEVEL);

void LightSwitch::Init()
{
	Nrf::Matter::BindingHandler::Init();
#ifdef CONFIG_CHIP_LIB_SHELL
	SwitchCommands::RegisterSwitchCommands();
#endif
}

void LightSwitch::InitiateActionSwitch(Action action)
{
	Nrf::Matter::BindingHandler::BindingData *data = Platform::New<Nrf::Matter::BindingHandler::BindingData>();
	if (data) {
		data->EndpointId = mLightSwitchEndpoint;
		data->ClusterId = Clusters::OnOff::Id;
		data->InvokeCommandFunc = SwitchChangedHandler;
		switch (action) {
		case Action::Toggle:
			data->CommandId = Clusters::OnOff::Commands::Toggle::Id;
			break;
		case Action::On:
			data->CommandId = Clusters::OnOff::Commands::On::Id;
			break;
		case Action::Off:
			data->CommandId = Clusters::OnOff::Commands::Off::Id;
			break;
		default:
			Platform::Delete(data);
			return;
		}
		Nrf::Matter::BindingHandler::RunBoundClusterAction(data);
	}
}

void LightSwitch::DimmerChangeBrightness()
{
	static uint16_t sBrightness;
	Nrf::Matter::BindingHandler::BindingData *data = Platform::New<Nrf::Matter::BindingHandler::BindingData>();
	if (data) {
		data->EndpointId = mLightSwitchEndpoint;
		data->CommandId = Clusters::LevelControl::Commands::MoveToLevel::Id;
		data->ClusterId = Clusters::LevelControl::Id;
		data->InvokeCommandFunc = SwitchChangedHandler;
		/* add to brightness 3 to approximate 1% step of brightness after each call dimmer change. */
		sBrightness += kOnePercentBrightnessApproximation;
		if (sBrightness > kMaximumBrightness) {
			sBrightness = 0;
		}
		data->Value = (uint8_t)sBrightness;
		Nrf::Matter::BindingHandler::RunBoundClusterAction(data);
	}
}

void LightSwitch::SwitchChangedHandler(const Binding::TableEntry &binding, OperationalDeviceProxy *deviceProxy,
				       Nrf::Matter::BindingHandler::BindingData &bindingData)
{
	if (binding.type == Binding::MATTER_MULTICAST_BINDING) {
		switch (bindingData.ClusterId) {
		case Clusters::OnOff::Id:
			OnOffProcessCommand(bindingData.CommandId, binding, nullptr, bindingData);
			break;
		case Clusters::LevelControl::Id:
			LevelControlProcessCommand(bindingData.CommandId, binding, nullptr, bindingData);
			break;
		default:
			LOG_ERR("Invalid binding group command data");
			break;
		}
	} else if (binding.type == Binding::MATTER_UNICAST_BINDING) {
		switch (bindingData.ClusterId) {
		case Clusters::OnOff::Id:
			OnOffProcessCommand(bindingData.CommandId, binding, deviceProxy, bindingData);
			break;
		case Clusters::LevelControl::Id:
			LevelControlProcessCommand(bindingData.CommandId, binding, deviceProxy, bindingData);
			break;
		default:
			LOG_ERR("Invalid binding unicast command data");
			break;
		}
	}
}

void LightSwitch::OnOffProcessCommand(CommandId commandId, const Binding::TableEntry &binding,
				      OperationalDeviceProxy *device,
				      Nrf::Matter::BindingHandler::BindingData &bindingData)
{
	CHIP_ERROR ret = CHIP_NO_ERROR;

	auto onSuccess = [dataPointer = Platform::New<Nrf::Matter::BindingHandler::BindingData>(bindingData)](
				 const ConcreteCommandPath &commandPath, const StatusIB &status,
				 const auto &dataResponse) {
		Nrf::Matter::BindingHandler::OnInvokeCommandSucces(dataPointer);
	};

	auto onFailure = [dataPointer = Platform::New<Nrf::Matter::BindingHandler::BindingData>(bindingData)](
				 CHIP_ERROR aError) mutable {
		Nrf::Matter::BindingHandler::OnInvokeCommandFailure(dataPointer, aError);
	};

	if (device) {
		/* We are validating connection is ready once here instead of multiple times in each case
		 * statement below. */
		VerifyOrDie(device->ConnectionReady());
	}

	switch (commandId) {
	case Clusters::OnOff::Commands::Toggle::Id:
		Clusters::OnOff::Commands::Toggle::Type toggleCommand;
		if (device) {
			ret = Controller::InvokeCommandRequest(device->GetExchangeManager(),
							       device->GetSecureSession().Value(), binding.remote,
							       toggleCommand, onSuccess, onFailure);
		} else {
			Messaging::ExchangeManager &exchangeMgr = Server::GetInstance().GetExchangeManager();
			ret = Controller::InvokeGroupCommandRequest(&exchangeMgr, binding.fabricIndex, binding.groupId,
								    toggleCommand);
		}
		break;

	case Clusters::OnOff::Commands::On::Id:
		Clusters::OnOff::Commands::On::Type onCommand;
		if (device) {
			ret = Controller::InvokeCommandRequest(device->GetExchangeManager(),
							       device->GetSecureSession().Value(), binding.remote,
							       onCommand, onSuccess, onFailure);
		} else {
			Messaging::ExchangeManager &exchangeMgr = Server::GetInstance().GetExchangeManager();
			ret = Controller::InvokeGroupCommandRequest(&exchangeMgr, binding.fabricIndex, binding.groupId,
								    onCommand);
		}
		break;

	case Clusters::OnOff::Commands::Off::Id:
		Clusters::OnOff::Commands::Off::Type offCommand;
		if (device) {
			ret = Controller::InvokeCommandRequest(device->GetExchangeManager(),
							       device->GetSecureSession().Value(), binding.remote,
							       offCommand, onSuccess, onFailure);
		} else {
			Messaging::ExchangeManager &exchangeMgr = Server::GetInstance().GetExchangeManager();
			ret = Controller::InvokeGroupCommandRequest(&exchangeMgr, binding.fabricIndex, binding.groupId,
								    offCommand);
		}
		break;
	default:
		LOG_DBG("Invalid binding command data - commandId is not supported");
		break;
	}
	if (CHIP_NO_ERROR != ret) {
		LOG_ERR("Invoke OnOff Command Request ERROR: %s", ErrorStr(ret));
	}
}

void LightSwitch::LevelControlProcessCommand(CommandId commandId, const Binding::TableEntry &binding,
					     OperationalDeviceProxy *device,
					     Nrf::Matter::BindingHandler::BindingData &bindingData)
{
	auto onSuccess = [dataPointer = Platform::New<Nrf::Matter::BindingHandler::BindingData>(bindingData)](
				 const ConcreteCommandPath &commandPath, const StatusIB &status,
				 const auto &dataResponse) {
		Nrf::Matter::BindingHandler::OnInvokeCommandSucces(dataPointer);
	};

	auto onFailure = [dataPointer = Platform::New<Nrf::Matter::BindingHandler::BindingData>(bindingData)](
				 CHIP_ERROR aError) mutable {
		Nrf::Matter::BindingHandler::OnInvokeCommandFailure(dataPointer, aError);
	};

	CHIP_ERROR ret = CHIP_NO_ERROR;

	if (device) {
		/* We are validating connection is ready once here instead of multiple times in each case
		 * statement below.
		 */
		VerifyOrDie(device->ConnectionReady());
	}

	switch (commandId) {
	case Clusters::LevelControl::Commands::MoveToLevel::Id: {
		Clusters::LevelControl::Commands::MoveToLevel::Type moveToLevelCommand;
		moveToLevelCommand.level = bindingData.Value;
		if (device) {
			ret = Controller::InvokeCommandRequest(device->GetExchangeManager(),
							       device->GetSecureSession().Value(), binding.remote,
							       moveToLevelCommand, onSuccess, onFailure);
		} else {
			Messaging::ExchangeManager &exchangeMgr = Server::GetInstance().GetExchangeManager();
			ret = Controller::InvokeGroupCommandRequest(&exchangeMgr, binding.fabricIndex, binding.groupId,
								    moveToLevelCommand);
		}
	} break;
	default:
		LOG_DBG("Invalid binding command data - commandId is not supported");
		break;
	}
	if (CHIP_NO_ERROR != ret) {
		LOG_ERR("Invoke Group Command Request ERROR: %s", ErrorStr(ret));
	}
}
```

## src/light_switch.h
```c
/*
 * Copyright (c) 2022 Nordic Semiconductor ASA
 *
 * SPDX-License-Identifier: LicenseRef-Nordic-5-Clause
 */

#pragma once
#include <app/util/basic-types.h>
#include <lib/core/CHIPError.h>

#include "binding/binding_handler.h"
#include "switch.h"

#include <atomic>

/** @class LightSwitch
 *  @brief Class for controlling a CHIP light bulb over a Thread network
 *
 *  Features:
 *  - discovering a CHIP light bulb which advertises itself by sending Thread multicast packets
 *  - toggling and dimming the connected CHIP light bulb by sending appropriate CHIP messages
 */
class LightSwitch : public Switch {
public:
	LightSwitch(chip::EndpointId switchEndpoint) : Switch(switchEndpoint) {}

	void Init() override;
	void InitiateActionSwitch(Action action) override;
	void DimmerChangeBrightness() override;

private:
	static void OnOffProcessCommand(chip::CommandId commandId,
					const chip::app::Clusters::Binding::TableEntry &binding,
					chip::OperationalDeviceProxy *device,
					Nrf::Matter::BindingHandler::BindingData &bindingData);

	static void LevelControlProcessCommand(chip::CommandId commandId,
					       const chip::app::Clusters::Binding::TableEntry &binding,
					       chip::OperationalDeviceProxy *device,
					       Nrf::Matter::BindingHandler::BindingData &bindingData);

	static void SwitchChangedHandler(const chip::app::Clusters::Binding::TableEntry &binding,
					 chip::OperationalDeviceProxy *deviceProxy,
					 Nrf::Matter::BindingHandler::BindingData &bindingData);

	constexpr static auto kOnePercentBrightnessApproximation = 3;
	constexpr static auto kMaximumBrightness = 254;
};
```
